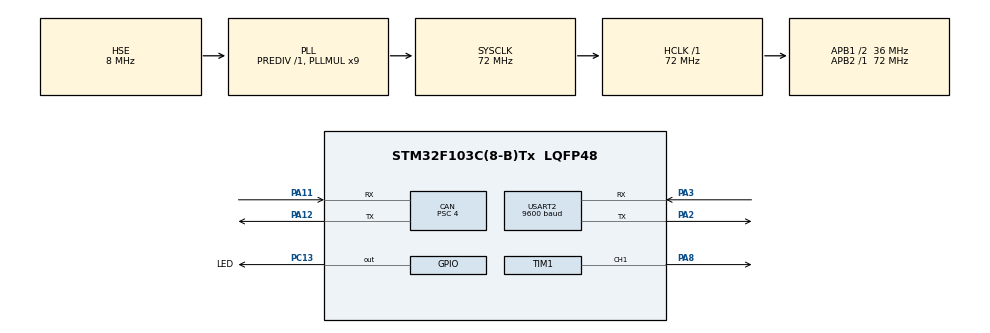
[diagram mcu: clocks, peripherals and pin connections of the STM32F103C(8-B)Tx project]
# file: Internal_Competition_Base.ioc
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Mcu.Family=STM32F1
RCC.PLLSourceVirtual=RCC_PLLSOURCE_HSE
PD1-OSC_OUT.Mode=HSE-External-Oscillator
PC13-TAMPER-RTC.Signal=GPIO_Output
PA11.Mode=Master
PD0-OSC_IN.Signal=RCC_OSC_IN
RCC.APB1CLKDivider=RCC_HCLK_DIV2
USART2.BaudRate=9600
CAN.CalculateTimeBit=1000
RCC.SYSCLKSource=RCC_SYSCLKSOURCE_PLLCLK
ProjectManager.StackSize=0x400
PD1-OSC_OUT.Signal=RCC_OSC_OUT
PA13.Signal=SYS_JTMS-SWDIO
PA3.Mode=Asynchronous
PA12.Signal=CAN_TX
CAN.BS2=CAN_BS2_2TQ
CAN.Prescaler=4
CAN.BS1=CAN_BS1_6TQ
SH.S_TIM1_CH1.0=TIM1_CH1,Output Compare1 CH1
ProjectManager.TargetToolchain=Makefile
RCC.HCLKFreq_Value=72000000
RCC.APB2TimFreq_Value=72000000
RCC.USBFreq_Value=72000000
RCC.AHBFreq_Value=72000000
PD0-OSC_IN.Mode=HSE-External-Oscillator
board=custom
PC13-TAMPER-RTC.GPIO_Label=LED
RCC.PLLMUL=RCC_PLL_MUL9
RCC.APB2Freq_Value=72000000
PA14.Mode=Serial_Wire
CAN.NART=DISABLE
PA8.Signal=S_TIM1_CH1
PC13-TAMPER-RTC.GPIO_Speed=GPIO_SPEED_FREQ_MEDIUM
PA13.Mode=Serial_Wire
Mcu.Name=STM32F103C(8-B)Tx
CAN.CalculateTimeQuantum=111.11111111111111
VP_TIM1_VS_ClockSourceINT.Mode=Internal
PA2.Signal=USART2_TX
RCC.SYSCLKFreq_VALUE=72000000
Mcu.Package=LQFP48
PA12.Mode=Master
USART2.VirtualMode=VM_ASYNC
PA11.Signal=CAN_RX
PA14.Signal=SYS_JTCK-SWCLK
ProjectManager.HeapSize=0x200
TIM1.Channel-Output\ Compare1\ CH1=TIM_CHANNEL_1
NVIC.PriorityGroup=NVIC_PRIORITYGROUP_4
RCC.APB1TimFreq_Value=72000000
PA2.Mode=Asynchronous
RCC.APB1Freq_Value=36000000
PA3.Signal=USART2_RX

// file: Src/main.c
/* USER CODE BEGIN Header */
/**
  ******************************************************************************
  * @file           : main.c
  * @brief          : Main program body
  ******************************************************************************
  * @attention
  *
  * <h2><center>&copy; Copyright (c) 2021 STMicroelectronics.
  * All rights reserved.</center></h2>
  *
  * This software component is licensed by ST under BSD 3-Clause license,
  * the "License"; You may not use this file except in compliance with the
  * License. You may obtain a copy of the License at:
  *                        opensource.org/licenses/BSD-3-Clause
  *
  ******************************************************************************
  */
/* USER CODE END Header */

#include "main.h"

/* USER CODE BEGIN Includes */
#include <os.h>
/* USER CODE END Includes */

CAN_HandleTypeDef hcan;

TIM_HandleTypeDef htim1;

UART_HandleTypeDef huart2;

void SystemClock_Config(void);
static void MX_GPIO_Init(void);
static void MX_TIM1_Init(void);
static void MX_USART2_UART_Init(void);
static void MX_CAN_Init(void);

int main(void)
{

  /* MCU Configuration--------------------------------------------------------*/

  /* Reset of all peripherals, Initializes the Flash interface and the Systick. */
  HAL_Init();

  /* Configure the system clock */
  SystemClock_Config();

  /* Initialize all configured peripherals */
  MX_GPIO_Init();
  MX_TIM1_Init();
  MX_USART2_UART_Init();
  MX_CAN_Init();
  /* USER CODE BEGIN 2 */
  startRTOS();
  uint8_t data_in[16];
  HAL_UART_Receive_IT(&huart2, data_in, 18);
  /* USER CODE END 2 */

  /* Infinite loop */
  /* USER CODE BEGIN WHILE */

  while (1)
  {
    // HAL_CAN_AddTxMessage(&hcan, &txHeader, )

    /* USER CODE END WHILE */

    /* USER CODE BEGIN 3 */

    }
    HAL_Delay(10);
  }
  /* USER CODE END 3 */

void SystemClock_Config(void)
{
  RCC_OscInitTypeDef RCC_OscInitStruct = {0};
  RCC_ClkInitTypeDef RCC_ClkInitStruct = {0};

  /** Initializes the CPU, AHB and APB busses clocks
  */
  RCC_OscInitStruct.OscillatorType = RCC_OSCILLATORTYPE_HSE;
  RCC_OscInitStruct.HSEState = RCC_HSE_ON;
  RCC_OscInitStruct.HSEPredivValue = RCC_HSE_PREDIV_DIV1;
  RCC_OscInitStruct.HSIState = RCC_HSI_ON;
  RCC_OscInitStruct.PLL.PLLState = RCC_PLL_ON;
  RCC_OscInitStruct.PLL.PLLSource = RCC_PLLSOURCE_HSE;
  RCC_OscInitStruct.PLL.PLLMUL = RCC_PLL_MUL9;
  if (HAL_RCC_OscConfig(&RCC_OscInitStruct) != HAL_OK)
  {
    Error_Handler();
  }
  /** Initializes the CPU, AHB and APB busses clocks
  */
  RCC_ClkInitStruct.ClockType = RCC_CLOCKTYPE_HCLK|RCC_CLOCKTYPE_SYSCLK
                              |RCC_CLOCKTYPE_PCLK1|RCC_CLOCKTYPE_PCLK2;
  RCC_ClkInitStruct.SYSCLKSource = RCC_SYSCLKSOURCE_PLLCLK;
  RCC_ClkInitStruct.AHBCLKDivider = RCC_SYSCLK_DIV1;
  RCC_ClkInitStruct.APB1CLKDivider = RCC_HCLK_DIV2;
  RCC_ClkInitStruct.APB2CLKDivider = RCC_HCLK_DIV1;

  if (HAL_RCC_ClockConfig(&RCC_ClkInitStruct, FLASH_LATENCY_2) != HAL_OK)
  {
    Error_Handler();
  }
}

static void MX_CAN_Init(void)
{

  hcan.Instance = CAN1;
  hcan.Init.Prescaler = 4;
  hcan.Init.Mode = CAN_MODE_NORMAL;
  hcan.Init.SyncJumpWidth = CAN_SJW_1TQ;
  hcan.Init.TimeSeg1 = CAN_BS1_6TQ;
  hcan.Init.TimeSeg2 = CAN_BS2_2TQ;
  hcan.Init.TimeTriggeredMode = DISABLE;
  hcan.Init.AutoBusOff = DISABLE;
  hcan.Init.AutoWakeUp = DISABLE;
  hcan.Init.AutoRetransmission = DISABLE;
  hcan.Init.ReceiveFifoLocked = DISABLE;
  hcan.Init.TransmitFifoPriority = DISABLE;
  if (HAL_CAN_Init(&hcan) != HAL_OK)
  {
    Error_Handler();
  }

}

static void MX_TIM1_Init(void)
{

  TIM_ClockConfigTypeDef sClockSourceConfig = {0};
  TIM_MasterConfigTypeDef sMasterConfig = {0};
  TIM_OC_InitTypeDef sConfigOC = {0};
  TIM_BreakDeadTimeConfigTypeDef sBreakDeadTimeConfig = {0};

  htim1.Instance = TIM1;
  htim1.Init.Prescaler = 0;
  htim1.Init.CounterMode = TIM_COUNTERMODE_UP;
  htim1.Init.Period = 0;
  htim1.Init.ClockDivision = TIM_CLOCKDIVISION_DIV1;
  htim1.Init.RepetitionCounter = 0;
  htim1.Init.AutoReloadPreload = TIM_AUTORELOAD_PRELOAD_DISABLE;
  if (HAL_TIM_Base_Init(&htim1) != HAL_OK)
  {
    Error_Handler();
  }
  sClockSourceConfig.ClockSource = TIM_CLOCKSOURCE_INTERNAL;
  if (HAL_TIM_ConfigClockSource(&htim1, &sClockSourceConfig) != HAL_OK)
  {
    Error_Handler();
  }
  if (HAL_TIM_OC_Init(&htim1) != HAL_OK)
  {
    Error_Handler();
  }
  sMasterConfig.MasterOutputTrigger = TIM_TRGO_RESET;
  sMasterConfig.MasterSlaveMode = TIM_MASTERSLAVEMODE_DISABLE;
  if (HAL_TIMEx_MasterConfigSynchronization(&htim1, &sMasterConfig) != HAL_OK)
  {
    Error_Handler();
  }
  sConfigOC.OCMode = TIM_OCMODE_TIMING;
  sConfigOC.Pulse = 0;
  sConfigOC.OCPolarity = TIM_OCPOLARITY_HIGH;
  sConfigOC.OCNPolarity = TIM_OCNPOLARITY_HIGH;
  sConfigOC.OCFastMode = TIM_OCFAST_DISABLE;
  sConfigOC.OCIdleState = TIM_OCIDLESTATE_RESET;
  sConfigOC.OCNIdleState = TIM_OCNIDLESTATE_RESET;
  if (HAL_TIM_OC_ConfigChannel(&htim1, &sConfigOC, TIM_CHANNEL_1) != HAL_OK)
  {
    Error_Handler();
  }
  sBreakDeadTimeConfig.OffStateRunMode = TIM_OSSR_DISABLE;
  sBreakDeadTimeConfig.OffStateIDLEMode = TIM_OSSI_DISABLE;
  sBreakDeadTimeConfig.LockLevel = TIM_LOCKLEVEL_OFF;
  sBreakDeadTimeConfig.DeadTime = 0;
  sBreakDeadTimeConfig.BreakState = TIM_BREAK_DISABLE;
  sBreakDeadTimeConfig.BreakPolarity = TIM_BREAKPOLARITY_HIGH;
  sBreakDeadTimeConfig.AutomaticOutput = TIM_AUTOMATICOUTPUT_DISABLE;
  if (HAL_TIMEx_ConfigBreakDeadTime(&htim1, &sBreakDeadTimeConfig) != HAL_OK)
  {
    Error_Handler();
  }
  HAL_TIM_MspPostInit(&htim1);

}

static void MX_USART2_UART_Init(void)
{

  /* USER CODE BEGIN USART2_Init 0 */
  RC_Init();
  uint8_t data_in[16];
  HAL_UART_Receive_IT(&huart2, data_in, sizeof(data_in));
  /* USER CODE END USART2_Init 0 */

  huart2.Instance = USART2;
  huart2.Init.BaudRate = 9600;
  huart2.Init.WordLength = UART_WORDLENGTH_8B;
  huart2.Init.StopBits = UART_STOPBITS_1;
  huart2.Init.Parity = UART_PARITY_NONE;
  huart2.Init.Mode = UART_MODE_TX_RX;
  huart2.Init.HwFlowCtl = UART_HWCONTROL_NONE;
  huart2.Init.OverSampling = UART_OVERSAMPLING_16;
  if (HAL_UART_Init(&huart2) != HAL_OK)
  {
    Error_Handler();
  }

}

static void MX_GPIO_Init(void)
{
  GPIO_InitTypeDef GPIO_InitStruct = {0};

  /* GPIO Ports Clock Enable */
  __HAL_RCC_GPIOC_CLK_ENABLE();
  __HAL_RCC_GPIOD_CLK_ENABLE();
  __HAL_RCC_GPIOA_CLK_ENABLE();

  /*Configure GPIO pin Output Level */
  HAL_GPIO_WritePin(LED_GPIO_Port, LED_Pin, GPIO_PIN_RESET);

  /*Configure GPIO pin : LED_Pin */
  GPIO_InitStruct.Pin = LED_Pin;
  GPIO_InitStruct.Mode = GPIO_MODE_OUTPUT_PP;
  GPIO_InitStruct.Pull = GPIO_NOPULL;
  GPIO_InitStruct.Speed = GPIO_SPEED_FREQ_MEDIUM;
  HAL_GPIO_Init(LED_GPIO_Port, &GPIO_InitStruct);

}

void Error_Handler(void)
{
}

/************************ (C) COPYRIGHT STMicroelectronics *****END OF FILE****/
